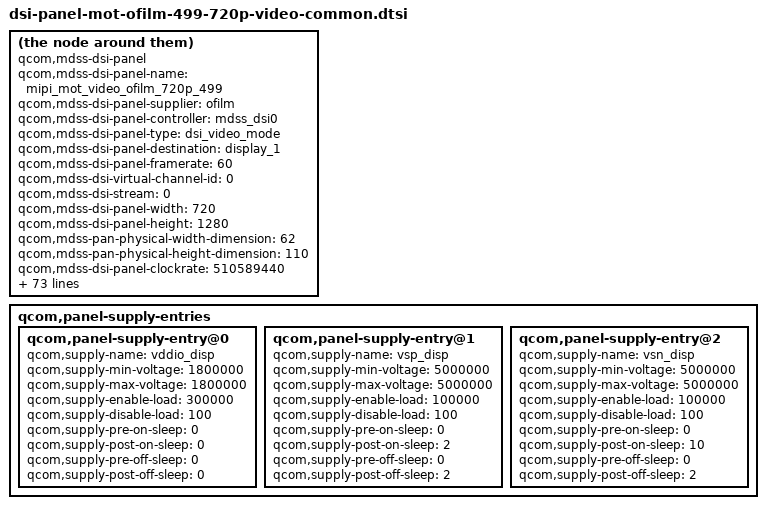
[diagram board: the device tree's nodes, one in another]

compatible = "qcom,mdss-dsi-panel";
qcom,mdss-dsi-panel-name = "mipi_mot_video_ofilm_720p_499";
qcom,mdss-dsi-panel-supplier = "ofilm";
qcom,mdss-dsi-panel-controller = <&mdss_dsi0>;
qcom,mdss-dsi-panel-type = "dsi_video_mode";
qcom,mdss-dsi-panel-destination = "display_1";
qcom,mdss-dsi-panel-framerate = <60>;
qcom,mdss-dsi-virtual-channel-id = <0>;
qcom,mdss-dsi-stream = <0>;
qcom,mdss-dsi-panel-width = <720>;
qcom,mdss-dsi-panel-height = <1280>;
qcom,mdss-pan-physical-width-dimension = <62>;
qcom,mdss-pan-physical-height-dimension = <110>;

qcom,mdss-dsi-panel-clockrate = <510589440>;
qcom,mdss-dsi-h-front-porch = <128>;
qcom,mdss-dsi-h-back-porch = <200>;
qcom,mdss-dsi-h-pulse-width = <20>;
qcom,mdss-dsi-h-sync-skew = <0>;
qcom,mdss-dsi-v-back-porch = <20>;
qcom,mdss-dsi-v-front-porch = <20>;
qcom,mdss-dsi-v-pulse-width = <8>;
qcom,mdss-dsi-h-left-border = <0>;
qcom,mdss-dsi-h-right-border = <0>;
qcom,mdss-dsi-v-top-border = <0>;
qcom,mdss-dsi-v-bottom-border = <0>;
qcom,mdss-dsi-bpp = <24>;
qcom,mdss-dsi-underflow-color = <0xff>;
qcom,mdss-dsi-border-color = <0>;

qcom,mdss-dsi-reset-sequence = <1 1>, <0 10>, <1 20>;
qcom,mdss-dsi-dis-reset-sequence = <1 10>, <0 0>;

qcom,mdss-dsi-on-command = [39 00 00 00 00 00 05 FF AA 55 25 01
	39 00 00 00 00 00 02 FC 08
	39 00 00 00 00 00 02 FC 00
	39 00 00 00 00 00 02 6F 21
	39 00 00 00 00 00 02 F7 01
	39 00 00 00 00 00 02 6F 21
	39 00 00 00 00 00 02 F7 00
	39 00 00 00 00 00 02 6F 1A
	39 00 00 00 00 00 02 F7 05
	39 00 00 00 00 00 05 FF AA 55 25 00
	39 00 00 00 00 00 06 F0 55 AA 52 08 02
	39 00 00 00 01 00 02 EE 02
	39 00 00 00 01 00 11 B0 00 67 00 4F 00 71 00 8B 00 A2 00 C9 00 E8 01 1C
	39 00 00 00 01 00 11 B1 01 4B 01 86 01 B5 01 FD 02 35 02 37 02 69 02 9E
	39 00 00 00 01 00 11 B2 02 BF 02 EC 03 06 03 31 03 4D 03 71 03 89 03 A7
	39 00 00 00 01 00 05 B3 03 D2 03 E8
	39 00 00 00 01 00 11 BC 00 3C 00 7E 00 9D 00 B5 00 C9 00 EA 01 03 01 2D
	39 00 00 00 00 00 11 BD 01 47 01 7E 01 A9 01 ED 02 24 02 25 02 59 02 92
	39 00 00 00 00 00 11 BE 02 B5 02 E6 03 0D 03 3A 03 57 03 7C 03 94 03 B2
	39 00 00 00 00 00 05 BF 03 DE 03 E7
	39 00 00 00 00 00 06 F0 55 AA 52 08 00
	39 00 00 00 00 00 04 D9 01 01 10
	15 00 00 00 00 00 02 51 CC
	15 00 00 00 00 00 02 53 2C
	15 00 00 00 00 00 02 55 01
	15 00 00 00 00 00 02 68 06
	15 00 00 00 00 00 02 36 03
	05 01 00 00 78 00 01 11
	05 01 00 00 64 00 01 29];		/* Display on */

qcom,mdss-dsi-off-command = [
	05 01 00 00 14 00 01 28
	05 01 00 00 78 00 01 10];

qcom,mdss-dsi-on-command-state = "dsi_lp_mode";
qcom,mdss-dsi-off-command-state = "dsi_lp_mode";

qcom,mdss-dsi-cabc-ui-command = [15 01 00 00 00 00 02 55 01];
qcom,mdss-dsi-cabc-ui-command-state = "dsi_hs_mode";
qcom,mdss-dsi-cabc-mv-command = [15 01 00 00 00 00 02 55 03];
qcom,mdss-dsi-cabc-mv-command-state = "dsi_hs_mode";
qcom,mdss-dsi-cabc-dis-command = [15 01 00 00 00 00 02 55 00];
qcom,mdss-dsi-cabc-dis-command-state = "dsi_hs_mode";
qcom,mdss-dsi-hbm-on-command = [15 01 00 00 00 00 02 51 FF];
qcom,mdss-dsi-hbm-on-command-state = "dsi_hs_mode";
qcom,mdss-dsi-hbm-off-command = [15 01 00 00 00 00 02 51 CC];
qcom,mdss-dsi-hbm-off-command-state = "dsi_hs_mode";
qcom,mdss-dsi-hbm-type = "lcd-dcs-wled";

qcom,mdss-dsi-h-sync-pulse = <1>;
qcom,mdss-dsi-traffic-mode = "burst_mode";
qcom,mdss-dsi-bllp-eof-power-mode;
qcom,mdss-dsi-bllp-power-mode;
qcom,mdss-dsi-lp11-init;
qcom,mdss-dsi-tx-eot-append;
qcom,mdss-dsi-dma-trigger = "trigger_sw";
qcom,mdss-dsi-mdp-trigger = "none";
qcom,mdss-dsi-lane-0-state;
qcom,mdss-dsi-lane-1-state;
qcom,mdss-dsi-lane-2-state;
qcom,mdss-dsi-lane-3-state;

qcom,mdss-dsi-panel-timings = [7C 20 14 00 46 48 1A 24 18 03 04 00];
qcom,mdss-dsi-t-clk-post = <0x04>;
qcom,mdss-dsi-t-clk-pre = <0x27>;

qcom,mdss-dsi-bl-min-level = <1>;
qcom,mdss-dsi-bl-max-level = <4095>;
qcom,mdss-dsi-bl-pmic-control-type = "bl_ctrl_wled";

qcom,cont-splash-enabled;
qcom,esd-check-enabled;
qcom,mdss-dsi-panel-status-check-mode = "reg_read";
qcom,mdss-dsi-panel-status-command = [06 01 00 01 00 00 01 0A];
qcom,mdss-dsi-panel-status-command-state = "dsi_hs_mode";
qcom,mdss-dsi-panel-status-read-length = <1>;
qcom,mdss-dsi-panel-status-value = <0x9C>;

qcom,panel-supply-entries {
	#address-cells = <1>;
	#size-cells = <0>;
	qcom,panel-supply-entry@0 {
		qcom,supply-name = "vddio_disp";
		qcom,supply-min-voltage = <1800000>;
		qcom,supply-max-voltage = <1800000>;
		qcom,supply-enable-load = <300000>;
		qcom,supply-disable-load = <100>;
		qcom,supply-pre-on-sleep = <0>;
		qcom,supply-post-on-sleep = <0>;
		qcom,supply-pre-off-sleep = <0>;
		qcom,supply-post-off-sleep = <0>;
	};
	qcom,panel-supply-entry@1 {
		qcom,supply-name = "vsp_disp";
		qcom,supply-min-voltage = <5000000>;
		qcom,supply-max-voltage = <5000000>;
		qcom,supply-enable-load = <100000>;
		qcom,supply-disable-load = <100>;
		qcom,supply-pre-on-sleep = <0>;
		qcom,supply-post-on-sleep = <2>;
		qcom,supply-pre-off-sleep = <0>;
		qcom,supply-post-off-sleep = <2>;
	};
	qcom,panel-supply-entry@2 {
		qcom,supply-name = "vsn_disp";
		qcom,supply-min-voltage = <5000000>;
		qcom,supply-max-voltage = <5000000>;
		qcom,supply-enable-load = <100000>;
		qcom,supply-disable-load = <100>;
		qcom,supply-pre-on-sleep = <0>;
		qcom,supply-post-on-sleep = <10>;
		qcom,supply-pre-off-sleep = <0>;
		qcom,supply-post-off-sleep = <2>;
	};
};
